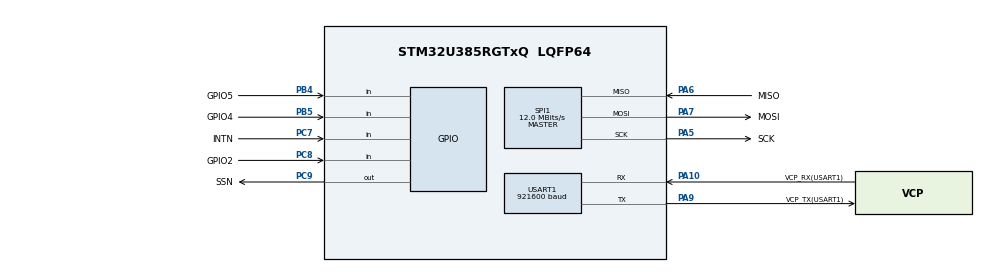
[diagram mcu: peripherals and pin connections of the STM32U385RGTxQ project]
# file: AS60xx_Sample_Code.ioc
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CORTEX_M33_NS.userName=CORTEX_M33
Mcu.Family=STM32U3
Mcu.Name=STM32U385RGTxQ
Mcu.Package=LQFP64
NVIC.PriorityGroup=NVIC_PRIORITYGROUP_4
PA10.GPIO_Label=VCP_RX(USART1)
PA10.Mode=Asynchronous
PA10.Signal=USART1_RX
PA13\ (JTMS/SWDIO).GPIO_Label=DEBUG_JTMS-SWDIO
PA13\ (JTMS/SWDIO).Signal=DEBUG_JTMS-SWDIO
PA14\ (JTCK/SWCLK).GPIO_Label=DEBUG_JTCK-SWCLK
PA14\ (JTCK/SWCLK).Signal=DEBUG_JTCK-SWCLK
PA15\ (JTDI).GPIO_Label=DEBUG_JTDI
PA15\ (JTDI).Signal=DEBUG_JTDI
PA5.GPIO_Label=SCK
PA5.Mode=Full_Duplex_Master
PA5.Signal=SPI1_SCK
PA6.GPIO_Label=MISO
PA6.Mode=Full_Duplex_Master
PA6.Signal=SPI1_MISO
PA7.GPIO_Label=MOSI
PA7.Mode=Full_Duplex_Master
PA7.Signal=SPI1_MOSI
PA9.GPIO_Label=VCP_TX(USART1)
PA9.Mode=Asynchronous
PA9.Signal=USART1_TX
PB3\ (JTDO/TRACESWO).GPIO_Label=DEBUG_JTDO-SWO
PB3\ (JTDO/TRACESWO).Signal=DEBUG_JTDO-SWO
PB4\ (NJTRST).GPIO_Label=GPIO5
PB4\ (NJTRST).Signal=GPIO_Input
PB5.GPIO_Label=GPIO4
PB5.Signal=GPIO_Input
PC13.GPIO_Label=BUTTON_USER
PC13.Signal=PWR_WKUP2
PC14-OSC32_IN\ (PC14).GPIO_Label=RCC_OSC32_IN
PC14-OSC32_IN\ (PC14).Signal=RCC_OSC32_IN
PC15-OSC32_OUT\ (PC15).GPIO_Label=RCC_OSC32_OUT
PC15-OSC32_OUT\ (PC15).Signal=RCC_OSC32_OUT
PC7.GPIO_Label=INTN
PC7.GPIO_PuPd=GPIO_PULLUP
PC7.Signal=GPIO_Input
PC8.GPIO_Label=GPIO2
PC8.Signal=GPIO_Input
PC9.GPIO_Label=SSN
PC9.Signal=GPIO_Output
ProjectManager.HeapSize=0x200
ProjectManager.StackSize=0x400
ProjectManager.TargetToolchain=STM32CubeIDE
RCC.ADCFreq_Value=96000000
RCC.AHBFreq_Value=96000000
RCC.APB1Freq_Value=96000000
RCC.APB1TimFreq_Value=96000000
RCC.APB2Freq_Value=96000000
RCC.APB2TimFreq_Value=96000000
RCC.APB3Freq_Value=96000000
RCC.CortexFreq_Value=12000000
RCC.HCLKFreq_Value=96000000
RCC.HSE_VALUE=16000000
RCC.HSI48_VALUE=48000000
RCC.HSI_VALUE=16000000
RCC.LSE_VALUE=32768
RCC.LSIDIV_VALUE=32000
RCC.MSISDIV=RCC_MSI_DIV1
RCC.SYSCLKFreq_VALUE=96000000
RCC.USBFreq_Value=48000000
RCC.USB_DIV=RCC_USB1CLKSOURCE_ICLK_DIV2
SPI1.BaudRatePrescaler=SPI_BAUDRATEPRESCALER_8
SPI1.CLKPhase=SPI_PHASE_2EDGE
SPI1.CalculateBaudRate=12.0 MBits/s
SPI1.DataSize=SPI_DATASIZE_8BIT
SPI1.Direction=SPI_DIRECTION_2LINES
SPI1.Mode=SPI_MODE_MASTER
SPI1.VirtualType=VM_MASTER
USART1.BaudRate=921600
USART1.VirtualMode-Asynchronous=VM_ASYNC
VP_PWR_VS_DBSignals.Mode=DisableDeadBatterySignals
VP_PWR_VS_LPOM.Mode=PowerOptimisation
VP_PWR_VS_SECSignals.Mode=Security/Privilege
board=NUCLEO-U385RG-Q

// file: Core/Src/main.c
/* USER CODE BEGIN Header */
/**
  ******************************************************************************
  * @file           : main.c
  * @brief          : Main program body
  ******************************************************************************
  * @attention
  *
  * Copyright (c) 2025 STMicroelectronics.
  * All rights reserved.
  *
  * This software is licensed under terms that can be found in the LICENSE file
  * in the root directory of this software component.
  * If no LICENSE file comes with this software, it is provided AS-IS.
  *
  ******************************************************************************
  */
/* USER CODE END Header */
#include "main.h"

/* USER CODE BEGIN Includes */

#ifdef EXAMPLE_BASIC_ULTRASOUND
  #include "ScioSense/01_AS60xx_Example_Basic_Ultrasound.h"
#endif
#ifdef EXAMPLE_ULTRASOUND_AND_TEMPERATURE
  #include "ScioSense/02_AS60xx_Example_Ultrasound_and_Temperature.h"
#endif
#ifdef EXAMPLE_AS6031F1
  #include "ScioSense/03_AS6031F1_Example.h"
#endif

/* USER CODE END Includes */

/* USER CODE BEGIN PD */
#define AS60XX_EXAMPLE  1
/* USER CODE END PD */

SPI_HandleTypeDef hspi1;

UART_HandleTypeDef huart1;

void SystemClock_Config(void);
static void MX_GPIO_Init(void);
static void MX_SPI1_Init(void);
static void MX_USART1_UART_Init(void);
/* USER CODE BEGIN PFP */
uint8_t SerialPrint(const char str[]);
/* USER CODE END PFP */

int main(void)
{

  /* MCU Configuration--------------------------------------------------------*/

  /* Reset of all peripherals, Initializes the Flash interface and the Systick. */
  HAL_Init();

  /* Configure the system clock */
  SystemClock_Config();

  /* Initialize all configured peripherals */
  MX_GPIO_Init();
  MX_SPI1_Init();
  MX_USART1_UART_Init();
  /* USER CODE BEGIN 2 */
  AS60xx_Example_Setup(&huart1, &hspi1);
  /* USER CODE END 2 */

  /* Infinite loop */
  while (1)
  {

    /* USER CODE BEGIN 3 */
      AS60xx_Example_Loop();
  }
  /* USER CODE END 3 */
}

void SystemClock_Config(void)
{
  RCC_OscInitTypeDef RCC_OscInitStruct = {0};
  RCC_ClkInitTypeDef RCC_ClkInitStruct = {0};

  /** Enable Epod Booster
  */
  if (HAL_RCCEx_EpodBoosterClkConfig(RCC_EPODBOOSTER_SOURCE_MSIS, RCC_EPODBOOSTER_DIV1) != HAL_OK)
  {
    Error_Handler();
  }
  if (HAL_PWREx_EnableEpodBooster() != HAL_OK)
  {
    Error_Handler();
  }

  /** Configure the main internal regulator output voltage
  */
  if (HAL_PWREx_ControlVoltageScaling(PWR_REGULATOR_VOLTAGE_SCALE1) != HAL_OK)
  {
    Error_Handler();
  }

  /** Set Flash latency before increasing MSIS
  */
  __HAL_FLASH_SET_LATENCY(FLASH_LATENCY_2);

  /** Initializes the CPU, AHB and APB buses clocks
  */
  RCC_OscInitStruct.OscillatorType = RCC_OSCILLATORTYPE_MSIS;
  RCC_OscInitStruct.MSISState = RCC_MSI_ON;
  RCC_OscInitStruct.MSISSource = RCC_MSI_RC0;
  RCC_OscInitStruct.MSISDiv = RCC_MSI_DIV1;
  if (HAL_RCC_OscConfig(&RCC_OscInitStruct) != HAL_OK)
  {
    Error_Handler();
  }

  /** Initializes the CPU, AHB and APB buses clocks
  */
  RCC_ClkInitStruct.ClockType = RCC_CLOCKTYPE_HCLK|RCC_CLOCKTYPE_SYSCLK
                              |RCC_CLOCKTYPE_PCLK1|RCC_CLOCKTYPE_PCLK2
                              |RCC_CLOCKTYPE_PCLK3;
  RCC_ClkInitStruct.SYSCLKSource = RCC_SYSCLKSOURCE_MSIS;
  RCC_ClkInitStruct.AHBCLKDivider = RCC_SYSCLK_DIV1;
  RCC_ClkInitStruct.APB1CLKDivider = RCC_HCLK_DIV1;
  RCC_ClkInitStruct.APB2CLKDivider = RCC_HCLK_DIV1;
  RCC_ClkInitStruct.APB3CLKDivider = RCC_HCLK_DIV1;

  if (HAL_RCC_ClockConfig(&RCC_ClkInitStruct, FLASH_LATENCY_2) != HAL_OK)
  {
    Error_Handler();
  }
}

static void MX_SPI1_Init(void)
{

  SPI_AutonomousModeConfTypeDef HAL_SPI_AutonomousMode_Cfg_Struct = {0};

  /* SPI1 parameter configuration*/
  hspi1.Instance = SPI1;
  hspi1.Init.Mode = SPI_MODE_MASTER;
  hspi1.Init.Direction = SPI_DIRECTION_2LINES;
  hspi1.Init.DataSize = SPI_DATASIZE_8BIT;
  hspi1.Init.CLKPolarity = SPI_POLARITY_LOW;
  hspi1.Init.CLKPhase = SPI_PHASE_2EDGE;
  hspi1.Init.NSS = SPI_NSS_SOFT;
  hspi1.Init.BaudRatePrescaler = SPI_BAUDRATEPRESCALER_8;
  hspi1.Init.FirstBit = SPI_FIRSTBIT_MSB;
  hspi1.Init.TIMode = SPI_TIMODE_DISABLE;
  hspi1.Init.CRCCalculation = SPI_CRCCALCULATION_DISABLE;
  hspi1.Init.CRCPolynomial = 0x7;
  hspi1.Init.NSSPMode = SPI_NSS_PULSE_DISABLE;
  hspi1.Init.NSSPolarity = SPI_NSS_POLARITY_LOW;
  hspi1.Init.FifoThreshold = SPI_FIFO_THRESHOLD_01DATA;
  hspi1.Init.MasterSSIdleness = SPI_MASTER_SS_IDLENESS_00CYCLE;
  hspi1.Init.MasterInterDataIdleness = SPI_MASTER_INTERDATA_IDLENESS_00CYCLE;
  hspi1.Init.MasterReceiverAutoSusp = SPI_MASTER_RX_AUTOSUSP_DISABLE;
  hspi1.Init.MasterKeepIOState = SPI_MASTER_KEEP_IO_STATE_DISABLE;
  hspi1.Init.IOSwap = SPI_IO_SWAP_DISABLE;
  hspi1.Init.ReadyMasterManagement = SPI_RDY_MASTER_MANAGEMENT_INTERNALLY;
  hspi1.Init.ReadyPolarity = SPI_RDY_POLARITY_HIGH;
  if (HAL_SPI_Init(&hspi1) != HAL_OK)
  {
    Error_Handler();
  }
  HAL_SPI_AutonomousMode_Cfg_Struct.TriggerState = SPI_AUTO_MODE_DISABLE;
  HAL_SPI_AutonomousMode_Cfg_Struct.TriggerSelection = SPI_GRP1_GPDMA_CH0_TCF_TRG;
  HAL_SPI_AutonomousMode_Cfg_Struct.TriggerPolarity = SPI_TRIG_POLARITY_RISING;
  if (HAL_SPIEx_SetConfigAutonomousMode(&hspi1, &HAL_SPI_AutonomousMode_Cfg_Struct) != HAL_OK)
  {
    Error_Handler();
  }

}

static void MX_USART1_UART_Init(void)
{

  huart1.Instance = USART1;
  huart1.Init.BaudRate = 921600;
  huart1.Init.WordLength = UART_WORDLENGTH_8B;
  huart1.Init.StopBits = UART_STOPBITS_1;
  huart1.Init.Parity = UART_PARITY_NONE;
  huart1.Init.Mode = UART_MODE_TX_RX;
  huart1.Init.HwFlowCtl = UART_HWCONTROL_NONE;
  huart1.Init.OverSampling = UART_OVERSAMPLING_16;
  huart1.Init.OneBitSampling = UART_ONE_BIT_SAMPLE_DISABLE;
  huart1.Init.ClockPrescaler = UART_PRESCALER_DIV1;
  huart1.AdvancedInit.AdvFeatureInit = UART_ADVFEATURE_NO_INIT;
  if (HAL_UART_Init(&huart1) != HAL_OK)
  {
    Error_Handler();
  }
  if (HAL_UARTEx_SetTxFifoThreshold(&huart1, UART_TXFIFO_THRESHOLD_1_8) != HAL_OK)
  {
    Error_Handler();
  }
  if (HAL_UARTEx_SetRxFifoThreshold(&huart1, UART_RXFIFO_THRESHOLD_1_8) != HAL_OK)
  {
    Error_Handler();
  }
  if (HAL_UARTEx_DisableFifoMode(&huart1) != HAL_OK)
  {
    Error_Handler();
  }

}

static void MX_GPIO_Init(void)
{
  GPIO_InitTypeDef GPIO_InitStruct = {0};

  /* GPIO Ports Clock Enable */
  __HAL_RCC_GPIOC_CLK_ENABLE();
  __HAL_RCC_GPIOA_CLK_ENABLE();
  __HAL_RCC_GPIOB_CLK_ENABLE();

  /*Configure GPIO pin Output Level */
  HAL_GPIO_WritePin(SSN_GPIO_Port, SSN_Pin, GPIO_PIN_RESET);

  /*Configure GPIO pin : INTN_Pin */
  GPIO_InitStruct.Pin = INTN_Pin;
  GPIO_InitStruct.Mode = GPIO_MODE_INPUT;
  GPIO_InitStruct.Pull = GPIO_PULLUP;
  HAL_GPIO_Init(INTN_GPIO_Port, &GPIO_InitStruct);

  /*Configure GPIO pin : GPIO2_Pin */
  GPIO_InitStruct.Pin = GPIO2_Pin;
  GPIO_InitStruct.Mode = GPIO_MODE_INPUT;
  GPIO_InitStruct.Pull = GPIO_NOPULL;
  HAL_GPIO_Init(GPIO2_GPIO_Port, &GPIO_InitStruct);

  /*Configure GPIO pin : SSN_Pin */
  GPIO_InitStruct.Pin = SSN_Pin;
  GPIO_InitStruct.Mode = GPIO_MODE_OUTPUT_PP;
  GPIO_InitStruct.Pull = GPIO_NOPULL;
  GPIO_InitStruct.Speed = GPIO_SPEED_FREQ_LOW;
  HAL_GPIO_Init(SSN_GPIO_Port, &GPIO_InitStruct);

  /*Configure GPIO pins : GPIO5_Pin GPIO4_Pin */
  GPIO_InitStruct.Pin = GPIO5_Pin|GPIO4_Pin;
  GPIO_InitStruct.Mode = GPIO_MODE_INPUT;
  GPIO_InitStruct.Pull = GPIO_NOPULL;
  HAL_GPIO_Init(GPIOB, &GPIO_InitStruct);

}

void Error_Handler(void)
{
  __disable_irq();
  while (1)
  {
  }
}
